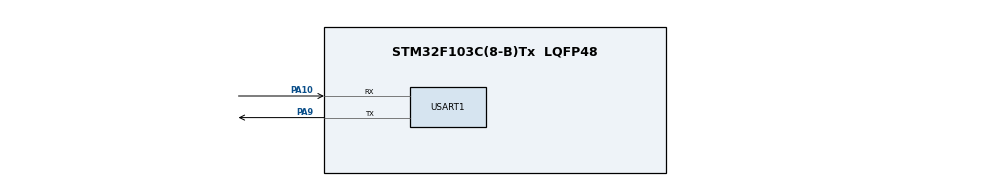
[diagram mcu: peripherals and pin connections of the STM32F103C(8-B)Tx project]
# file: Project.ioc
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Mcu.Family=STM32F1
Mcu.Name=STM32F103C(8-B)Tx
Mcu.Package=LQFP48
NVIC.PriorityGroup=NVIC_PRIORITYGROUP_4
PA10.Mode=Asynchronous
PA10.Signal=USART1_RX
PA13.Mode=Serial_Wire
PA13.Signal=SYS_JTMS-SWDIO
PA14.Mode=Serial_Wire
PA14.Signal=SYS_JTCK-SWCLK
PA9.Mode=Asynchronous
PA9.Signal=USART1_TX
ProjectManager.HeapSize=0x200
ProjectManager.StackSize=0x400
ProjectManager.TargetToolchain=MDK-ARM V5.32
RCC.APB1Freq_Value=8000000
RCC.APB2Freq_Value=8000000
USART1.VirtualMode=VM_ASYNC
board=custom

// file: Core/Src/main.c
/* USER CODE BEGIN Header */
/**
  ******************************************************************************
  * @file           : main.c
  * @brief          : Main program body
  ******************************************************************************
  * @attention
  *
  * Copyright (c) 2026 STMicroelectronics.
  * All rights reserved.
  *
  * This software is licensed under terms that can be found in the LICENSE file
  * in the root directory of this software component.
  * If no LICENSE file comes with this software, it is provided AS-IS.
  *
  ******************************************************************************
  */
/* USER CODE END Header */
#include "main.h"
#include "usart.h"
#include "gpio.h"

/* USER CODE BEGIN Includes */
#include "zdt42.h"
/* USER CODE END Includes */

/* USER CODE BEGIN PD */
#define ZDT42_MOTOR_ID      0x05U
#define ZDT42_TEST_STAGE    0U
#define ZDT42_TEST_WAIT_MS  3000U
/* USER CODE END PD */

/* USER CODE BEGIN PV */
ZDT42_Status zdt_status = ZDT42_OK;
uint8_t zdt_version[5] = {0};
int16_t zdt_speed = 0;
float zdt_angle = 0.0f;
int32_t zdt_target_angle = 0;
volatile uint8_t test_done = 0;
/* USER CODE END PV */

void SystemClock_Config(void);
/* USER CODE BEGIN PFP */
static void ZDT42_AbortMotion(uint8_t id);
static ZDT42_Status ZDT42_TestReadOnly(uint8_t id);
static ZDT42_Status ZDT42_TestBasicControl(uint8_t id);
static ZDT42_Status ZDT42_TestSpeed(uint8_t id);
static ZDT42_Status ZDT42_TestRelativePosition(uint8_t id);
static ZDT42_Status ZDT42_TestAbsolutePosition(uint8_t id);
static ZDT42_Status ZDT42_TestRun(uint8_t id, uint8_t stage);
/* USER CODE END PFP */

int main(void)
{

  /* MCU Configuration--------------------------------------------------------*/

  /* Reset of all peripherals, Initializes the Flash interface and the Systick. */
  HAL_Init();

  /* Configure the system clock */
  SystemClock_Config();

  /* Initialize all configured peripherals */
  MX_GPIO_Init();
  MX_USART1_UART_Init();
  /* USER CODE BEGIN 2 */
  zdt_status = ZDT42_Init(&huart1);

  if (zdt_status == ZDT42_OK)
  {
      HAL_Delay(1000);
      zdt_status = ZDT42_TestRun(ZDT42_MOTOR_ID, ZDT42_TEST_STAGE);
  }

  test_done = 1;
  /* USER CODE END 2 */

  /* Infinite loop */
  while (1)
  {

  }
}

void SystemClock_Config(void)
{
  RCC_OscInitTypeDef RCC_OscInitStruct = {0};
  RCC_ClkInitTypeDef RCC_ClkInitStruct = {0};

  /** Initializes the RCC Oscillators according to the specified parameters
  * in the RCC_OscInitTypeDef structure.
  */
  RCC_OscInitStruct.OscillatorType = RCC_OSCILLATORTYPE_HSI;
  RCC_OscInitStruct.HSIState = RCC_HSI_ON;
  RCC_OscInitStruct.HSICalibrationValue = RCC_HSICALIBRATION_DEFAULT;
  RCC_OscInitStruct.PLL.PLLState = RCC_PLL_NONE;
  if (HAL_RCC_OscConfig(&RCC_OscInitStruct) != HAL_OK)
  {
    Error_Handler();
  }

  /** Initializes the CPU, AHB and APB buses clocks
  */
  RCC_ClkInitStruct.ClockType = RCC_CLOCKTYPE_HCLK|RCC_CLOCKTYPE_SYSCLK
                              |RCC_CLOCKTYPE_PCLK1|RCC_CLOCKTYPE_PCLK2;
  RCC_ClkInitStruct.SYSCLKSource = RCC_SYSCLKSOURCE_HSI;
  RCC_ClkInitStruct.AHBCLKDivider = RCC_SYSCLK_DIV1;
  RCC_ClkInitStruct.APB1CLKDivider = RCC_HCLK_DIV1;
  RCC_ClkInitStruct.APB2CLKDivider = RCC_HCLK_DIV1;

  if (HAL_RCC_ClockConfig(&RCC_ClkInitStruct, FLASH_LATENCY_0) != HAL_OK)
  {
    Error_Handler();
  }
}

/* USER CODE BEGIN 4 */
static void ZDT42_AbortMotion(uint8_t id)
{
    (void)ZDT42_Stop(id);
    (void)ZDT42_Enable(id, 0);
}

static ZDT42_Status ZDT42_TestReadOnly(uint8_t id)
{
    ZDT42_Status status;

    status = ZDT42_ReadVersion(id, zdt_version, sizeof(zdt_version));
    if (status != ZDT42_OK)
    {
        return status;
    }

    status = ZDT42_ReadSpeed(id, &zdt_speed);
    if (status != ZDT42_OK)
    {
        return status;
    }

    return ZDT42_ReadPosition(id, &zdt_angle);
}

static ZDT42_Status ZDT42_TestBasicControl(uint8_t id)
{
    ZDT42_Status status;

    status = ZDT42_Enable(id, 1);
    if (status != ZDT42_OK)
    {
        ZDT42_AbortMotion(id);
        return status;
    }

    HAL_Delay(500U);

    status = ZDT42_Stop(id);
    if (status != ZDT42_OK)
    {
        ZDT42_AbortMotion(id);
        return status;
    }

    HAL_Delay(200U);

    status = ZDT42_Enable(id, 0);
    if (status != ZDT42_OK)
    {
        ZDT42_AbortMotion(id);
    }

    return status;
}

static ZDT42_Status ZDT42_TestSpeed(uint8_t id)
{
    ZDT42_Status status;

    status = ZDT42_Enable(id, 1);
    if (status != ZDT42_OK)
    {
        ZDT42_AbortMotion(id);
        return status;
    }

    status = ZDT42_SetSpeed(id, 10, 10);
    if (status != ZDT42_OK)
    {
        ZDT42_AbortMotion(id);
        return status;
    }

    HAL_Delay(ZDT42_TEST_WAIT_MS);

    status = ZDT42_ReadSpeed(id, &zdt_speed);
    if (status != ZDT42_OK)
    {
        ZDT42_AbortMotion(id);
        return status;
    }

    status = ZDT42_Stop(id);
    if (status != ZDT42_OK)
    {
        ZDT42_AbortMotion(id);
        return status;
    }

    HAL_Delay(500U);

    status = ZDT42_SetSpeed(id, -10, 10);
    if (status != ZDT42_OK)
    {
        ZDT42_AbortMotion(id);
        return status;
    }

    HAL_Delay(ZDT42_TEST_WAIT_MS);

    status = ZDT42_ReadSpeed(id, &zdt_speed);
    if (status != ZDT42_OK)
    {
        ZDT42_AbortMotion(id);
        return status;
    }

    status = ZDT42_Stop(id);
    if (status != ZDT42_OK)
    {
        ZDT42_AbortMotion(id);
        return status;
    }

    HAL_Delay(500U);

    status = ZDT42_Enable(id, 0);
    if (status != ZDT42_OK)
    {
        ZDT42_AbortMotion(id);
    }

    return status;
}

static ZDT42_Status ZDT42_TestRelativePosition(uint8_t id)
{
    ZDT42_Status status;

    status = ZDT42_Enable(id, 1);
    if (status != ZDT42_OK)
    {
        ZDT42_AbortMotion(id);
        return status;
    }

    status = ZDT42_MoveRelative(id, 90, 10, 10);
    if (status != ZDT42_OK)
    {
        ZDT42_AbortMotion(id);
        return status;
    }

    HAL_Delay(ZDT42_TEST_WAIT_MS);

    status = ZDT42_ReadPosition(id, &zdt_angle);
    if (status != ZDT42_OK)
    {
        ZDT42_AbortMotion(id);
        return status;
    }

    status = ZDT42_MoveRelative(id, -90, 10, 10);
    if (status != ZDT42_OK)
    {
        ZDT42_AbortMotion(id);
        return status;
    }

    HAL_Delay(ZDT42_TEST_WAIT_MS);

    status = ZDT42_ReadPosition(id, &zdt_angle);
    if (status != ZDT42_OK)
    {
        ZDT42_AbortMotion(id);
        return status;
    }

    status = ZDT42_Stop(id);
    if (status != ZDT42_OK)
    {
        ZDT42_AbortMotion(id);
        return status;
    }

    status = ZDT42_Enable(id, 0);
    if (status != ZDT42_OK)
    {
        ZDT42_AbortMotion(id);
    }

    return status;
}

static ZDT42_Status ZDT42_TestAbsolutePosition(uint8_t id)
{
    ZDT42_Status status;
    int32_t start_angle;

    status = ZDT42_Enable(id, 1);
    if (status != ZDT42_OK)
    {
        ZDT42_AbortMotion(id);
        return status;
    }

    status = ZDT42_ReadPosition(id, &zdt_angle);
    if (status != ZDT42_OK)
    {
        ZDT42_AbortMotion(id);
        return status;
    }
    start_angle = (int32_t)zdt_angle;

    zdt_target_angle = start_angle + 90;
    status = ZDT42_MoveAbsolute(id, zdt_target_angle, 10, 10);
    if (status != ZDT42_OK)
    {
        ZDT42_AbortMotion(id);
        return status;
    }

    HAL_Delay(ZDT42_TEST_WAIT_MS);

    status = ZDT42_ReadPosition(id, &zdt_angle);
    if (status != ZDT42_OK)
    {
        ZDT42_AbortMotion(id);
        return status;
    }

    status = ZDT42_MoveAbsolute(id, start_angle, 10, 10);
    if (status != ZDT42_OK)
    {
        ZDT42_AbortMotion(id);
        return status;
    }

    HAL_Delay(ZDT42_TEST_WAIT_MS);

    status = ZDT42_ReadPosition(id, &zdt_angle);
    if (status != ZDT42_OK)
    {
        ZDT42_AbortMotion(id);
        return status;
    }

    status = ZDT42_Stop(id);
    if (status != ZDT42_OK)
    {
        ZDT42_AbortMotion(id);
        return status;
    }

    status = ZDT42_Enable(id, 0);
    if (status != ZDT42_OK)
    {
        ZDT42_AbortMotion(id);
    }

    return status;
}

static ZDT42_Status ZDT42_TestRun(uint8_t id, uint8_t stage)
{
    ZDT42_Status status;

    if (stage > 4U)
    {
        return ZDT42_PARAM_ERROR;
    }

    /* 无论哪个阶段，都先验证只读通信。 */
    status = ZDT42_TestReadOnly(id);
    if (status != ZDT42_OK)
    {
        return status;
    }

    switch (stage)
    {
        case 0U:
            return ZDT42_OK;
        case 1U:
            return ZDT42_TestBasicControl(id);
        case 2U:
            return ZDT42_TestSpeed(id);
        case 3U:
            return ZDT42_TestRelativePosition(id);
        case 4U:
            return ZDT42_TestAbsolutePosition(id);
        default:
            return ZDT42_PARAM_ERROR;
    }
}
/* USER CODE END 4 */

void Error_Handler(void)
{
  __disable_irq();
  while (1)
  {
  }
}
